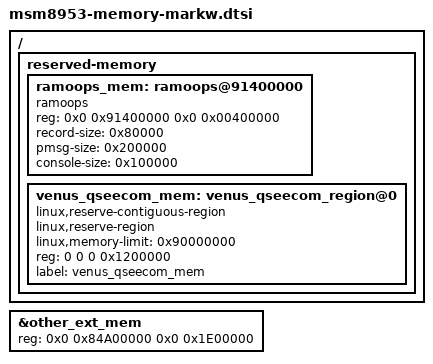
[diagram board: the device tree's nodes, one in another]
/*
 * Copyright (c) 2017, The Linux Foundation. All rights reserved.
 *
 * This program is free software; you can redistribute it and/or modify
 * it under the terms of the GNU General Public License version 2 and
 * only version 2 as published by the Free Software Foundation.
 *
 * This program is distributed in the hope that it will be useful,
 * but WITHOUT ANY WARRANTY; without even the implied warranty of
 * MERCHANTABILITY or FITNESS FOR A PARTICULAR PURPOSE.  See the
 * GNU General Public License for more details.
 */

&other_ext_mem {
    reg = <0x0 0x84A00000 0x0 0x1E00000>;
};

/ {
	reserved-memory {
		ramoops_mem: ramoops@91400000 {
			compatible = "ramoops";
			reg = <0x0 0x91400000 0x0 0x00400000>;
			record-size = <0x80000>;
			pmsg-size = <0x200000>;
			console-size = <0x100000>;
		};
		venus_qseecom_mem: venus_qseecom_region@0 {
			linux,reserve-contiguous-region;
			linux,reserve-region;
			linux,memory-limit = <0x90000000>;
			reg = <0 0 0 0x1200000>;
			label = "venus_qseecom_mem";
		};
	};
};
